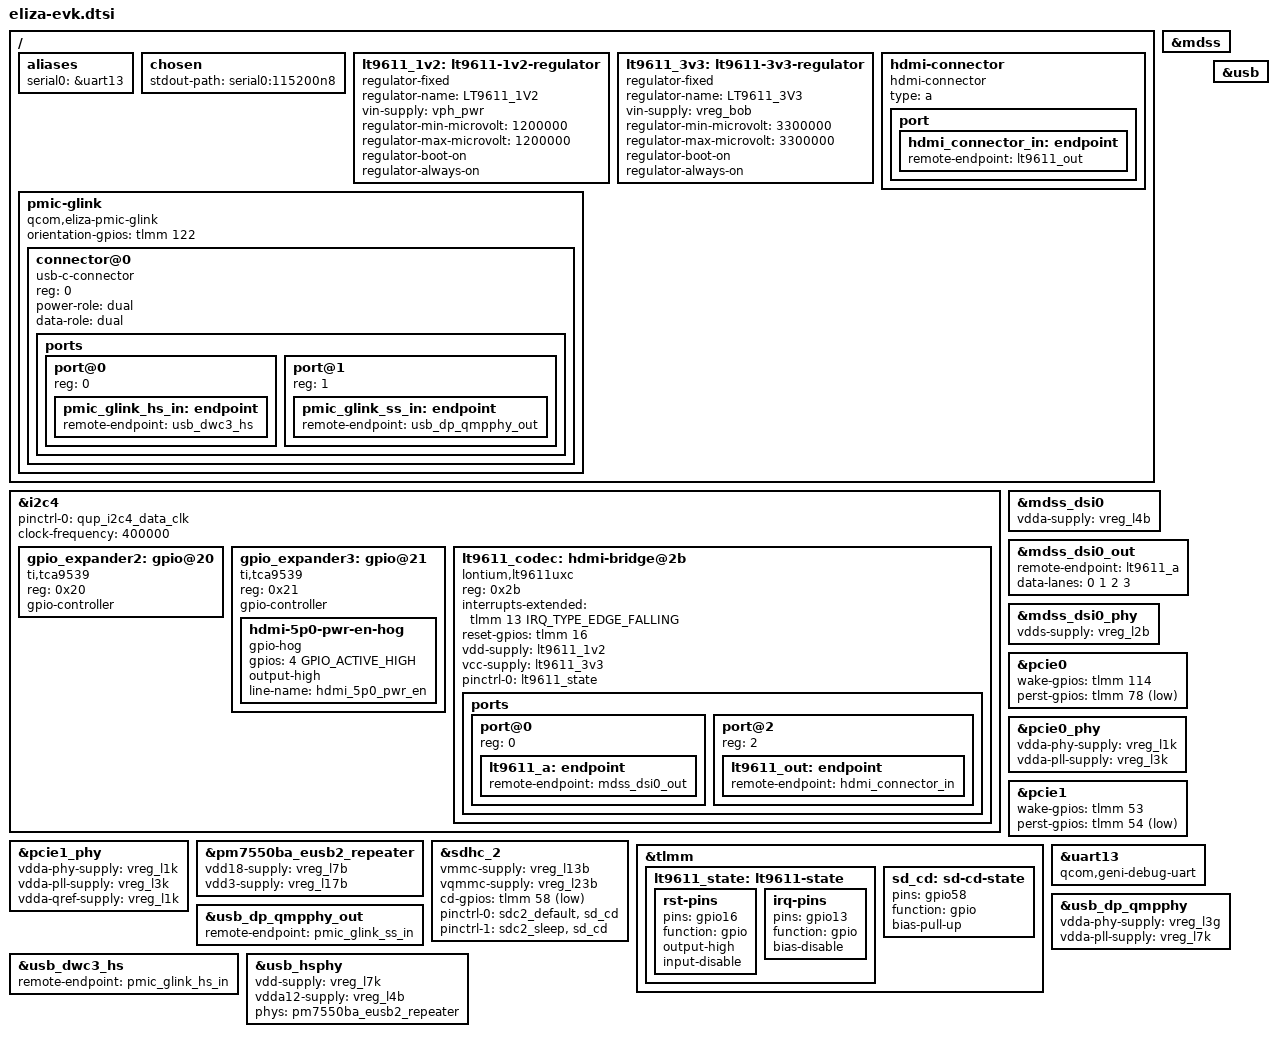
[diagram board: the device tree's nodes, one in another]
// SPDX-License-Identifier: BSD-3-Clause
/*
 * Copyright (c) Qualcomm Technologies, Inc. and/or its subsidiaries.
 */

/ {
	aliases {
		serial0 = &uart13;
	};

	chosen {
		stdout-path = "serial0:115200n8";
	};

	lt9611_1v2: lt9611-1v2-regulator {
		compatible = "regulator-fixed";
		regulator-name = "LT9611_1V2";

		vin-supply = <&vph_pwr>;
		regulator-min-microvolt = <1200000>;
		regulator-max-microvolt = <1200000>;
		regulator-boot-on;
		regulator-always-on;
	};

	lt9611_3v3: lt9611-3v3-regulator {
		compatible = "regulator-fixed";
		regulator-name = "LT9611_3V3";

		vin-supply = <&vreg_bob>;
		regulator-min-microvolt = <3300000>;
		regulator-max-microvolt = <3300000>;
		regulator-boot-on;
		regulator-always-on;
	};

	hdmi-connector {
		compatible = "hdmi-connector";
		type = "a";

		port {
			hdmi_connector_in: endpoint {
				remote-endpoint = <&lt9611_out>;
			};
		};
	};

	pmic-glink {
		compatible = "qcom,eliza-pmic-glink",
			     "qcom,sm8550-pmic-glink",
			     "qcom,pmic-glink";
		#address-cells = <1>;
		#size-cells = <0>;
		orientation-gpios = <&tlmm 122 GPIO_ACTIVE_HIGH>;

		connector@0 {
			compatible = "usb-c-connector";
			reg = <0>;

			power-role = "dual";
			data-role = "dual";

			ports {
				#address-cells = <1>;
				#size-cells = <0>;

				port@0 {
					reg = <0>;

					pmic_glink_hs_in: endpoint {
						remote-endpoint = <&usb_dwc3_hs>;
					};
				};

				port@1 {
					reg = <1>;

					pmic_glink_ss_in: endpoint {
						remote-endpoint = <&usb_dp_qmpphy_out>;
					};
				};
			};
		};
	};
};

&i2c4 {
	pinctrl-0 = <&qup_i2c4_data_clk>;
	pinctrl-names = "default";

	clock-frequency = <400000>;

	status = "okay";

	gpio_expander2: gpio@20 {
		compatible = "ti,tca9539";
		reg = <0x20>;

		gpio-controller;
		#gpio-cells = <2>;
	};

	gpio_expander3: gpio@21 {
		compatible = "ti,tca9539";
		reg = <0x21>;

		gpio-controller;
		#gpio-cells = <2>;

		hdmi-5p0-pwr-en-hog {
			gpio-hog;
			gpios = <4 GPIO_ACTIVE_HIGH>;
			output-high;
			line-name = "hdmi_5p0_pwr_en";
		};
	};

	lt9611_codec: hdmi-bridge@2b {
		compatible = "lontium,lt9611uxc";
		reg = <0x2b>;

		interrupts-extended = <&tlmm 13 IRQ_TYPE_EDGE_FALLING>;
		reset-gpios = <&tlmm 16 GPIO_ACTIVE_HIGH>;

		vdd-supply = <&lt9611_1v2>;
		vcc-supply = <&lt9611_3v3>;

		pinctrl-names = "default";
		pinctrl-0 = <&lt9611_state>;

		ports {
			#address-cells = <1>;
			#size-cells = <0>;

			port@0 {
				reg = <0>;

				lt9611_a: endpoint {
					remote-endpoint = <&mdss_dsi0_out>;
				};
			};

			port@2 {
				reg = <2>;

				lt9611_out: endpoint {
					remote-endpoint = <&hdmi_connector_in>;
				};
			};
		};
	};
};

&mdss {
	status = "okay";
};

&mdss_dsi0 {
	vdda-supply = <&vreg_l4b>;

	status = "okay";
};

&mdss_dsi0_out {
	remote-endpoint = <&lt9611_a>;
	data-lanes = <0 1 2 3>;
};

&mdss_dsi0_phy {
	vdds-supply = <&vreg_l2b>;

	status = "okay";
};

&pcie0 {
	wake-gpios = <&tlmm 114 GPIO_ACTIVE_HIGH>;
	perst-gpios = <&tlmm 78 GPIO_ACTIVE_LOW>;

	status = "okay";
};

&pcie0_phy {
	vdda-phy-supply = <&vreg_l1k>;
	vdda-pll-supply = <&vreg_l3k>;

	status = "okay";
};

&pcie1 {
	wake-gpios = <&tlmm 53 GPIO_ACTIVE_HIGH>;
	perst-gpios = <&tlmm 54 GPIO_ACTIVE_LOW>;

	status = "okay";
};

&pcie1_phy {
	vdda-phy-supply = <&vreg_l1k>;
	vdda-pll-supply = <&vreg_l3k>;
	vdda-qref-supply = <&vreg_l1k>;

	status = "okay";
};

&pm7550ba_eusb2_repeater {
	vdd18-supply = <&vreg_l7b>;
	vdd3-supply = <&vreg_l17b>;
};

&sdhc_2 {
	vmmc-supply = <&vreg_l13b>;
	vqmmc-supply = <&vreg_l23b>;

	cd-gpios = <&tlmm 58 GPIO_ACTIVE_LOW>;

	pinctrl-0 = <&sdc2_default>, <&sd_cd>;
	pinctrl-1 = <&sdc2_sleep>, <&sd_cd>;
	pinctrl-names = "default", "sleep";

	status = "okay";
};

&tlmm {
	lt9611_state: lt9611-state {
		rst-pins {
			pins = "gpio16";
			function = "gpio";

			output-high;
			input-disable;
		};

		irq-pins {
			pins = "gpio13";
			function = "gpio";
			bias-disable;
		};
	};

	sd_cd: sd-cd-state {
		pins = "gpio58";
		function = "gpio";
		bias-pull-up;
	};
};

&uart13 {
	compatible = "qcom,geni-debug-uart";

	status = "okay";
};

&usb {
	status = "okay";
};

&usb_dp_qmpphy {
	vdda-phy-supply = <&vreg_l3g>;
	vdda-pll-supply = <&vreg_l7k>;

	status = "okay";
};

&usb_dp_qmpphy_out {
	remote-endpoint = <&pmic_glink_ss_in>;
};

&usb_dwc3_hs {
	remote-endpoint = <&pmic_glink_hs_in>;
};

&usb_hsphy {
	vdd-supply = <&vreg_l7k>;
	vdda12-supply = <&vreg_l4b>;

	phys = <&pm7550ba_eusb2_repeater>;

	status = "okay";
};
